# nrf9220_sysctrl register map
Vendor: Nordic Semiconductor; Series: nRF92; File version: 1
Registers are 32-bit, read-write, reset 0x0 unless marked. A register's access mark holds for its fields unless they carry their own. Offsets are from the block's base; [hi:lo] are bit positions; lines under a group give offsets from that group; 'fields as' and 'values as' point back to an identical list.

## SWEXT130 — SWEXT peripheral 0
Base 0x5F96C000
Same registers: SWEXT131 0x5F97D000, SWEXT132 0x5F97E000, SWEXT133 0x5F97F000
0x00 TASKS_PWRUP wo — Power up switch
  [0] TASKS_PWRUP
    1=Trigger task
0x04 TASKS_PWRDOWN wo — Power down switch
  [0] TASKS_PWRDOWN
    1=Trigger task
0x100 EVENTS_READY — Power up done
  [0] EVENTS_READY
    0=NotGenerated (Event not generated); 1=Generated (Event generated)
0x104 EVENTS_SETTLED — Settled flag
  [0] EVENTS_SETTLED
    values as EVENTS_READY.EVENTS_READY
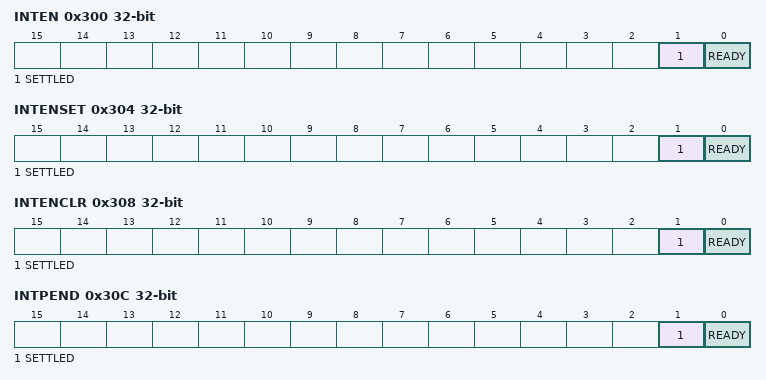
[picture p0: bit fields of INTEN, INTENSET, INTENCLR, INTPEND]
0x300 INTEN — Enable or disable interrupt
  [1] SETTLED — Enable or disable interrupt for event SETTLED
    0=Disabled; 1=Enabled
  [0] READY — Enable or disable interrupt for event READY
    0=Disabled; 1=Enabled
0x304 INTENSET — Enable interrupt
  [1] SETTLED — Write '1' to enable interrupt for event SETTLED
    on read: 0=Disabled (Read: Disabled); 1=Enabled (Read: Enabled) | on write: 1=Set (Enable)
  [0] READY — Write '1' to enable interrupt for event READY
    values as SETTLED
0x308 INTENCLR — Disable interrupt
  [1] SETTLED — Write '1' to disable interrupt for event SETTLED
    on read: 0=Disabled (Read: Disabled); 1=Enabled (Read: Enabled) | on write: 1=Clear (Disable)
  [0] READY — Write '1' to disable interrupt for event READY
    values as SETTLED
0x30C INTPEND ro — Pending interrupts
  [1] SETTLED — Read pending status of interrupt for event SETTLED
    on read: 0=NotPending (Read: Not pending); 1=Pending (Read: Pending)
  [0] READY — Read pending status of interrupt for event READY
    values as SETTLED
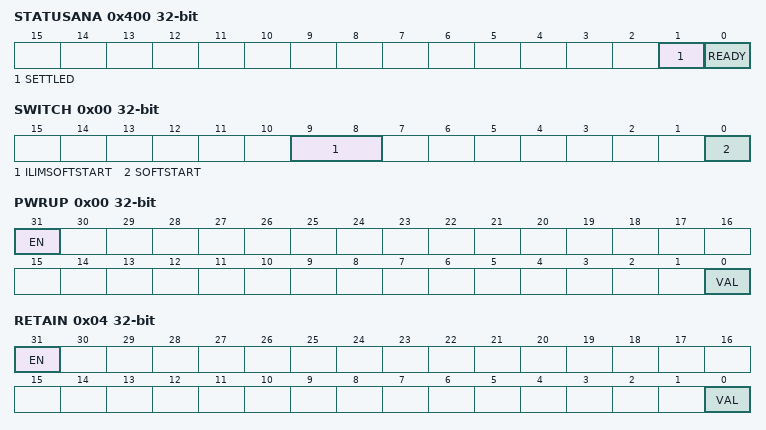
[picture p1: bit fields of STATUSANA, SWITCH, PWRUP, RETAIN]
0x400 STATUSANA ro — Status of analog module output signals
  [1] SETTLED — Current value of the SETTLED signal from the analog module
  [0] READY — Current value of the READY signal from the analog module
0x410 CONFIG group — Unspecified
  0x00 SWITCH — Switch configuration
    [9:8] ILIMSOFTSTART — Switch soft start current limiter
      0=IlimDefault (Default current limitattion); 1=Ilim1x5 (1.5x current limitation); 2=Ilim2x0 (2.0x current limitation); 3=Ilim0x5 (0.5x current limitation)
    [0] SOFTSTART — Switch soft start
      0=Enabled (Soft start enabled); 1=Disabled (Soft start disabled)
  0x04 PDCLAMP — Powerdown ground clamp
    [0] CLAMPENABLE — Clamp output to gnd when switch is powered down
      0=Disabled (Powerdown ground clamp disabled); 1=Enabled (Powerdown ground clamp enabled)
0x480 MIRROR reset 0x1 — Enable LOCK for mirrored registers
  [0] LOCK — Lock for mirrored registers
    0=Disabled (Lock disabled); 1=Enabled (Lock enabled)
0x500 OVERRIDE group — Unspecified
  0x00 PWRUP — Override the PWRUP signal to the analog module
    [31] EN — Enable the override
      0=Disabled (Override is disabled); 1=Enabled (Override is enabled)
    [0] VAL — Override value for the signal
  0x04 RETAIN — Override the RETAIN signal to the analog module
    fields as OVERRIDE.PWRUP
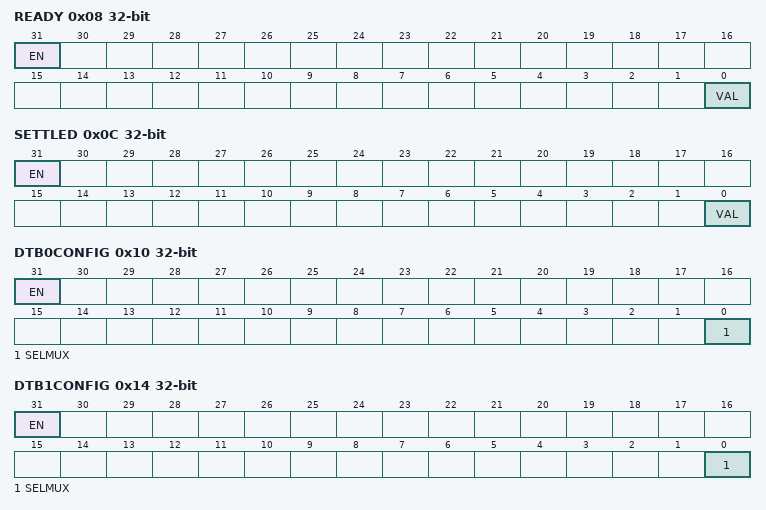
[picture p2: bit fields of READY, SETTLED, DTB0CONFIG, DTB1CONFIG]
  0x08 READY — Override the READY signal from the analog module
    [31] EN — Enable the override
      values as OVERRIDE.PWRUP.EN
    [0] VAL — Current value of the signal
  0x0C SETTLED — Override the SETTLED signal from the analog module
    fields as OVERRIDE.READY
0x600 DFT group — Unspecified
  0x10 DTB0CONFIG — Digital Test Bus 0 (DTB0) configuration
    [31] EN — Enable the digital test bus
      0=Disabled (Digital test bus is disabled); 1=Enabled (Digital test bus is enabled)
    [0] SELMUX — Select multiplexer for DTB0
      0=Spare0 (None selected, logic 0); 1=PwrupSw
  0x14 DTB1CONFIG — Digital Test Bus 1 (DTB1) configuration
    [31] EN — Enable the digital test bus
      values as DFT.DTB0CONFIG.EN
    [0] SELMUX — Select multiplexer for DTB1
      0=READY_P_SW; 1=SETTLED_P_SW
  0x1C DTB3CONFIG — Digital Test Bus 3 (DTB3) configuration
    [27] PWRUPDELTEST — Enable the PWRUP delay test circuit
      0=Disabled (PWRUP delay test circuit is disabled); 1=Enabled (PWRUP delay test circuit is enabled)
